AUTOSAR XML (schema 4-0-3)
package /ECU_Abstractions
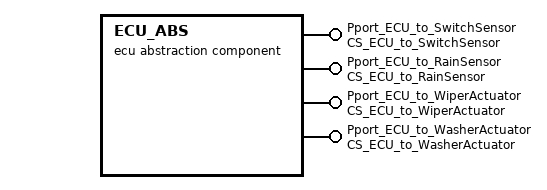
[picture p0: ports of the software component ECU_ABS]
  ecu abstraction sw component type ECU_ABS
    4 x provide port:
      Pport_ECU_to_SwitchSensor: provided-interface=CS_ECU_to_SwitchSensor
      Pport_ECU_to_RainSensor: provided-interface=CS_ECU_to_RainSensor
      Pport_ECU_to_WiperActuator: provided-interface=CS_ECU_to_WiperActuator
      Pport_ECU_to_WasherActuator: provided-interface=CS_ECU_to_WasherActuator
    behavior IB_ECU_ABS
      4 x operation invoked event:
        OIE_ECU_to_SwitchSensor: start-on-event=RE_ECU_to_SwitchSensor, operation=Pport_ECU_to_SwitchSensor.CS_Oper_ECU_to_SwitchSensor
        OIE_ECU_to_WiperActuator: start-on-event=RE_ECU_to_WiperActuator, operation=Pport_ECU_to_WiperActuator.CS_Oper_ECU_to_WiperActuator
        OIE_ECU_to_RainSensor: start-on-event=RE_ECU_to_RainSensor, operation=Pport_ECU_to_RainSensor.CS_Oper_ECU_to_RainSensor
        OIE_ECU_to_WasherActuator: start-on-event=RE_ECU_to_WasherActuator, operation=Pport_ECU_to_WasherActuator.CS_Oper_ECU_to_WasherActuator
      4 x runnable:
        RE_ECU_to_RainSensor
        RE_ECU_to_WiperActuator: symbol=RE_ECU_to_WiperMotor
        RE_ECU_to_SwitchSensor
        RE_ECU_to_WasherActuator: symbol=RE_ECU_to_Washer
package /Applications
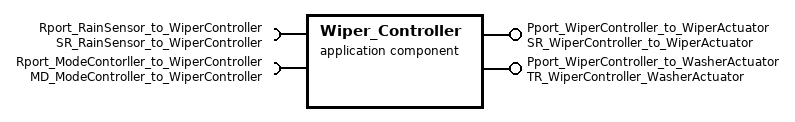
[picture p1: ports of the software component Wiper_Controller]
  application sw component type Wiper_Controller
    require port Rport_RainSensor_to_WiperController: required-interface=SR_RainSensor_to_WiperController
    provide port Pport_WiperController_to_WiperActuator: provided-interface=SR_WiperController_to_WiperActuator
    require port Rport_ModeContorller_to_WiperController: required-interface=MD_ModeController_to_WiperController
    provide port Pport_WiperController_to_WasherActuator: provided-interface=TR_WiperController_WasherActuator
    behavior IB_Wiper_Controller: data-type-mapping=ModeType
      5 x swc mode switch event, all with activation=ON-ENTRY:
        MSE_Mode_Auto: start-on-event=RE_Mode_Auto, mode=Rport_ModeContorller_to_WiperController.Switch_ModeGroup.Auto
          disabled-mode:
            Rport_ModeContorller_to_WiperController.Switch_ModeGroup.Wiper_Lv{1..3}
        MSE_Mode_Lv1: start-on-event=RE_Mode_Lv1, mode=Rport_ModeContorller_to_WiperController.Switch_ModeGroup.Wiper_Lv1
          disabled-mode:
            Rport_ModeContorller_to_WiperController.Switch_ModeGroup.Auto
            Rport_ModeContorller_to_WiperController.Switch_ModeGroup.Wiper_Lv2
            Rport_ModeContorller_to_WiperController.Switch_ModeGroup.Wiper_Lv3
        MSE_Mode_Lv2: start-on-event=RE_Mode_Lv2, mode=Rport_ModeContorller_to_WiperController.Switch_ModeGroup.Wiper_Lv2
          disabled-mode:
            Rport_ModeContorller_to_WiperController.Switch_ModeGroup.Auto
            Rport_ModeContorller_to_WiperController.Switch_ModeGroup.Wiper_Lv1
            Rport_ModeContorller_to_WiperController.Switch_ModeGroup.Wiper_Lv3
        MSE_Mode_Lv3: start-on-event=RE_Mode_Lv3, mode=Rport_ModeContorller_to_WiperController.Switch_ModeGroup.Wiper_Lv3
          disabled-mode:
            Rport_ModeContorller_to_WiperController.Switch_ModeGroup.Auto
            Rport_ModeContorller_to_WiperController.Switch_ModeGroup.Wiper_Lv1
            Rport_ModeContorller_to_WiperController.Switch_ModeGroup.Wiper_Lv2
        MSE_Mode_Washer: start-on-event=RE_Trigger_Washer, mode=Rport_ModeContorller_to_WiperController.Switch_ModeGroup.Washer
      implicit-inter-runnable-variables:
        data IRV_Wiper_Speed: type=uint8
      5 x runnable:
        RE_Mode_Auto
          data-receive-point-by-arguments:
            access DRPA_rain_sensor_value_0: accessed-variable=Rport_RainSensor_to_WiperController.rain_sensor_value
          data-send-points:
            access DSP_wiper_speed_value_0: accessed-variable=Pport_WiperController_to_WiperActuator.wiper_speed_value
          written-local-variables:
            access WrittenLocalVariables_VariableAccess_0: accessed-variable=IRV_Wiper_Speed
        RE_Mode_Lv1
          data-send-points:
            access DSP_wiper_speed_value_0: accessed-variable=Pport_WiperController_to_WiperActuator.wiper_speed_value
          written-local-variables:
            access WrittenLocalVariables_VariableAccess_0: accessed-variable=IRV_Wiper_Speed
        RE_Mode_Lv2
          data-send-points:
            access DSP_wiper_speed_value_0: accessed-variable=Pport_WiperController_to_WiperActuator.wiper_speed_value
          written-local-variables:
            access WrittenLocalVariables_VariableAccess_0: accessed-variable=IRV_Wiper_Speed
        RE_Mode_Lv3
          data-send-points:
            access DSP_wiper_speed_value_0: accessed-variable=Pport_WiperController_to_WiperActuator.wiper_speed_value
          written-local-variables:
            access WrittenLocalVariables_VariableAccess_0: accessed-variable=IRV_Wiper_Speed
        RE_Trigger_Washer: external-triggering-point=Pport_WiperController_to_WasherActuator.washer_value
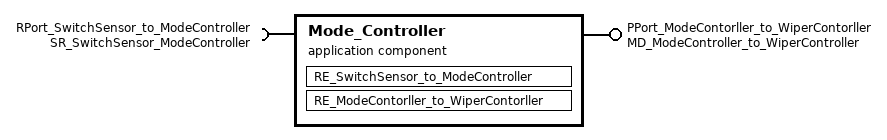
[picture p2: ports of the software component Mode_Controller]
  application sw component type Mode_Controller
    provide port PPort_ModeContorller_to_WiperContorller: provided-interface=MD_ModeController_to_WiperController
    require port RPort_SwitchSensor_to_ModeController: required-interface=SR_SwitchSensor_ModeController
    behavior IB_Mode_Controller: data-type-mapping=ModeType
      data received event DRE_SwitchSensor_to_ModeController: start-on-event=RE_SwitchSensor_to_ModeController, data=RPort_SwitchSensor_to_ModeController.switch_sensor_value
      runnable RE_SwitchSensor_to_ModeController
        data-receive-point-by-arguments:
          access DRPA_switch_sensor_value: accessed-variable=RPort_SwitchSensor_to_ModeController.switch_sensor_value
      runnable RE_ModeContorller_to_WiperContorller
        mode switch point ModeSwitchPoint: mode-group=PPort_ModeContorller_to_WiperContorller.Switch_ModeGroup
package /Sensors_and_Actuators
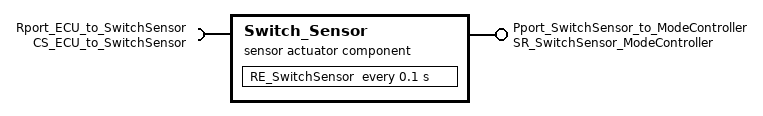
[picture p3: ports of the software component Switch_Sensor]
  sensor actuator sw component type Switch_Sensor
    require port Rport_ECU_to_SwitchSensor: required-interface=CS_ECU_to_SwitchSensor
    provide port Pport_SwitchSensor_to_ModeController: provided-interface=SR_SwitchSensor_ModeController
    behavior IB_Switch_Sensor
      timing event TE_100ms: start-on-event=RE_SwitchSensor, period=0.1
      runnable RE_SwitchSensor
        data-send-points:
          access DSP_switch_sensor_value: accessed-variable=Pport_SwitchSensor_to_ModeController.switch_sensor_value
        sync call SynchronousServerCallPoint: operation=Rport_ECU_to_SwitchSensor.CS_Oper_ECU_to_SwitchSensor
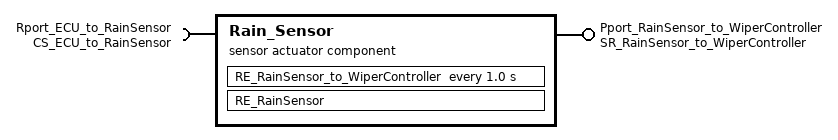
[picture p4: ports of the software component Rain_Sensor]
  sensor actuator sw component type Rain_Sensor
    require port Rport_ECU_to_RainSensor: required-interface=CS_ECU_to_RainSensor
    provide port Pport_RainSensor_to_WiperController: provided-interface=SR_RainSensor_to_WiperController
    behavior IB_Rain_Sensor
      timing event TE_1s: start-on-event=RE_RainSensor_to_WiperController, period=1.0
      runnable RE_RainSensor
        sync call SynchronousServerCallPoint: operation=Rport_ECU_to_RainSensor.CS_Oper_ECU_to_RainSensor
      runnable RE_RainSensor_to_WiperController
        data-send-points:
          access DSP_rain_sensor_value: accessed-variable=Pport_RainSensor_to_WiperController.rain_sensor_value
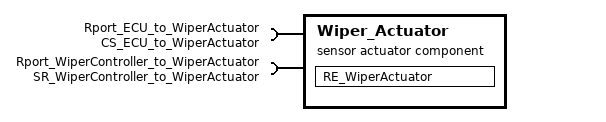
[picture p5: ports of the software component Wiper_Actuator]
  sensor actuator sw component type Wiper_Actuator
    require port Rport_ECU_to_WiperActuator: required-interface=CS_ECU_to_WiperActuator
    require port Rport_WiperController_to_WiperActuator: required-interface=SR_WiperController_to_WiperActuator
    behavior IB_Wiper_Actuator: supports-multiple-instantiation=true
      data received event DRE_WiperActuator: start-on-event=RE_WiperActuator, data=Rport_WiperController_to_WiperActuator.wiper_speed_value
      runnable RE_WiperActuator: symbol=RE_WiperMotor
        data-receive-point-by-arguments:
          access DRPA_wiper_Speed_Value_0: accessed-variable=Rport_WiperController_to_WiperActuator.wiper_speed_value
        sync call SynchronousServerCallPoint_0: operation=Rport_ECU_to_WiperActuator.CS_Oper_ECU_to_WiperActuator
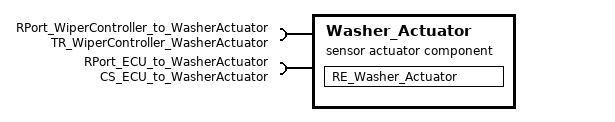
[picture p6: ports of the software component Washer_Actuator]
  sensor actuator sw component type Washer_Actuator
    require port RPort_WiperController_to_WasherActuator: required-interface=TR_WiperController_WasherActuator
    require port RPort_ECU_to_WasherActuator: required-interface=CS_ECU_to_WasherActuator
    behavior IB_Washer_Actuator
      external trigger occurred event TR_Wahser_Actuator: start-on-event=RE_Washer_Actuator, trigger=RPort_WiperController_to_WasherActuator.washer_value
      runnable RE_Washer_Actuator
        sync call SynchronousServerCallPoint: operation=RPort_ECU_to_WasherActuator.CS_Oper_ECU_to_WasherActuator
